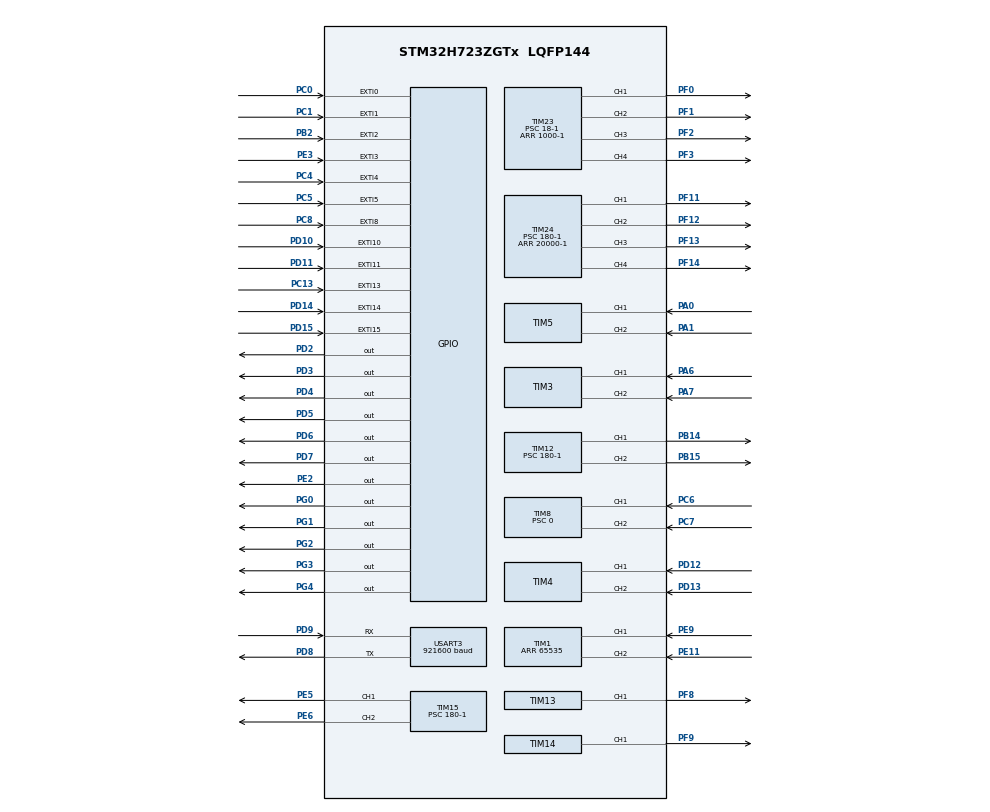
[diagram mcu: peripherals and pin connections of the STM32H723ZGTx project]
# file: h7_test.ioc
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CORTEX_M7.default_mode_Activation=1
Dma.Request0=USART3_RX
Dma.Request1=USART3_TX
Dma.USART3_RX.0.Direction=DMA_PERIPH_TO_MEMORY
Dma.USART3_RX.0.EventEnable=DISABLE
Dma.USART3_RX.0.FIFOMode=DMA_FIFOMODE_DISABLE
Dma.USART3_RX.0.Instance=DMA1_Stream0
Dma.USART3_RX.0.MemDataAlignment=DMA_MDATAALIGN_BYTE
Dma.USART3_RX.0.MemInc=DMA_MINC_ENABLE
Dma.USART3_RX.0.Mode=DMA_CIRCULAR
Dma.USART3_RX.0.PeriphDataAlignment=DMA_PDATAALIGN_BYTE
Dma.USART3_RX.0.PeriphInc=DMA_PINC_DISABLE
Dma.USART3_RX.0.Polarity=HAL_DMAMUX_REQ_GEN_RISING
Dma.USART3_RX.0.Priority=DMA_PRIORITY_VERY_HIGH
Dma.USART3_RX.0.RequestNumber=1
Dma.USART3_RX.0.SignalID=NONE
Dma.USART3_RX.0.SyncEnable=DISABLE
Dma.USART3_RX.0.SyncPolarity=HAL_DMAMUX_SYNC_NO_EVENT
Dma.USART3_RX.0.SyncRequestNumber=1
Dma.USART3_RX.0.SyncSignalID=NONE
Dma.USART3_TX.1.Direction=DMA_MEMORY_TO_PERIPH
Dma.USART3_TX.1.EventEnable=DISABLE
Dma.USART3_TX.1.FIFOMode=DMA_FIFOMODE_DISABLE
Dma.USART3_TX.1.Instance=DMA1_Stream1
Dma.USART3_TX.1.MemDataAlignment=DMA_MDATAALIGN_BYTE
Dma.USART3_TX.1.MemInc=DMA_MINC_ENABLE
Dma.USART3_TX.1.Mode=DMA_NORMAL
Dma.USART3_TX.1.PeriphDataAlignment=DMA_PDATAALIGN_BYTE
Dma.USART3_TX.1.PeriphInc=DMA_PINC_DISABLE
Dma.USART3_TX.1.Polarity=HAL_DMAMUX_REQ_GEN_RISING
Dma.USART3_TX.1.Priority=DMA_PRIORITY_VERY_HIGH
Dma.USART3_TX.1.RequestNumber=1
Dma.USART3_TX.1.SignalID=NONE
Dma.USART3_TX.1.SyncEnable=DISABLE
Dma.USART3_TX.1.SyncPolarity=HAL_DMAMUX_SYNC_NO_EVENT
Dma.USART3_TX.1.SyncRequestNumber=1
Dma.USART3_TX.1.SyncSignalID=NONE
FREERTOS.Tasks01=defaultTask,24,3000,StartDefaultTask,Default,NULL,Dynamic,NULL,NULL
Mcu.Family=STM32H7
Mcu.Name=STM32H723ZGTx
Mcu.Package=LQFP144
NVIC.DMA1_Stream0_IRQn=true\:5\:0\:false\:false\:true\:true\:false\:true\:true
NVIC.DMA1_Stream1_IRQn=true\:5\:0\:false\:false\:true\:true\:false\:true\:true
NVIC.EXTI0_IRQn=true\:5\:0\:false\:false\:true\:true\:true\:true\:true
NVIC.EXTI15_10_IRQn=true\:5\:0\:false\:false\:true\:true\:true\:true\:true
NVIC.EXTI1_IRQn=true\:5\:0\:false\:false\:true\:true\:true\:true\:true
NVIC.EXTI2_IRQn=true\:5\:0\:false\:false\:true\:true\:true\:true\:true
NVIC.EXTI3_IRQn=true\:5\:0\:false\:false\:true\:true\:true\:true\:true
NVIC.PriorityGroup=NVIC_PRIORITYGROUP_4
NVIC.TIM6_DAC_IRQn=true\:15\:0\:false\:false\:true\:false\:false\:true\:true
NVIC.TIM7_IRQn=true\:5\:0\:false\:false\:true\:true\:true\:true\:true
NVIC.TimeBase=TIM6_DAC_IRQn
NVIC.TimeBaseIP=TIM6
NVIC.USART3_IRQn=true\:5\:0\:false\:false\:true\:true\:true\:true\:true
PA0.Signal=S_TIM5_CH1
PA1.Signal=S_TIM5_CH2
PA13(JTMS/SWDIO).Mode=Serial_Wire
PA13(JTMS/SWDIO).Signal=DEBUG_JTMS-SWDIO
PA14(JTCK/SWCLK).Mode=Serial_Wire
PA14(JTCK/SWCLK).Signal=DEBUG_JTCK-SWCLK
PA6.Signal=S_TIM3_CH1
PA7.Signal=S_TIM3_CH2
PB14.Signal=S_TIM12_CH1
PB15.Signal=S_TIM12_CH2
PB2.GPIO_ModeDefaultEXTI=GPIO_MODE_IT_FALLING
PB2.GPIO_PuPd=GPIO_PULLUP
PB2.Signal=GPXTI2
PC0.GPIO_ModeDefaultEXTI=GPIO_MODE_IT_FALLING
PC0.GPIO_PuPd=GPIO_PULLUP
PC0.Signal=GPXTI0
PC1.GPIO_ModeDefaultEXTI=GPIO_MODE_IT_FALLING
PC1.GPIO_PuPd=GPIO_PULLUP
PC1.Signal=GPXTI1
PC13.GPIO_ModeDefaultEXTI=GPIO_MODE_IT_FALLING
PC13.GPIO_PuPd=GPIO_PULLUP
PC13.Signal=GPXTI13
PC14-OSC32_IN.Mode=LSE-External-Oscillator
PC14-OSC32_IN.Signal=RCC_OSC32_IN
PC15-OSC32_OUT.Mode=LSE-External-Oscillator
PC15-OSC32_OUT.Signal=RCC_OSC32_OUT
PC4.GPIO_ModeDefaultEXTI=GPIO_MODE_IT_FALLING
PC4.GPIO_PuPd=GPIO_PULLUP
PC4.Signal=GPXTI4
PC5.GPIO_ModeDefaultEXTI=GPIO_MODE_IT_FALLING
PC5.GPIO_PuPd=GPIO_PULLUP
PC5.Signal=GPXTI5
PC6.Signal=S_TIM8_CH1
PC7.Signal=S_TIM8_CH2
PC8.GPIO_ModeDefaultEXTI=GPIO_MODE_IT_FALLING
PC8.GPIO_PuPd=GPIO_PULLUP
PC8.Signal=GPXTI8
PD10.GPIO_ModeDefaultEXTI=GPIO_MODE_IT_FALLING
PD10.GPIO_PuPd=GPIO_PULLUP
PD10.Signal=GPXTI10
PD11.GPIO_ModeDefaultEXTI=GPIO_MODE_IT_FALLING
PD11.GPIO_PuPd=GPIO_PULLUP
PD11.Signal=GPXTI11
PD12.Signal=S_TIM4_CH1
PD13.Signal=S_TIM4_CH2
PD14.GPIO_ModeDefaultEXTI=GPIO_MODE_IT_FALLING
PD14.GPIO_PuPd=GPIO_PULLUP
PD14.Signal=GPXTI14
PD15.GPIO_ModeDefaultEXTI=GPIO_MODE_IT_FALLING
PD15.GPIO_PuPd=GPIO_PULLUP
PD15.Signal=GPXTI15
PD2.Signal=GPIO_Output
PD3.Signal=GPIO_Output
PD4.Signal=GPIO_Output
PD5.Signal=GPIO_Output
PD6.Signal=GPIO_Output
PD7.Signal=GPIO_Output
PD8.Mode=Asynchronous
PD8.Signal=USART3_TX
PD9.Mode=Asynchronous
PD9.Signal=USART3_RX
PE11.Signal=S_TIM1_CH2
PE2.Signal=GPIO_Output
PE3.GPIO_ModeDefaultEXTI=GPIO_MODE_IT_FALLING
PE3.GPIO_PuPd=GPIO_PULLUP
PE3.Signal=GPXTI3
PE5.Signal=S_TIM15_CH1
PE6.Signal=S_TIM15_CH2
PE9.Signal=S_TIM1_CH1
PF0.Mode=PWM Generation1 CH1
PF0.Signal=TIM23_CH1
PF1.Signal=S_TIM23_CH2
PF11.Mode=PWM Generation1 CH1
PF11.Signal=TIM24_CH1
PF12.Signal=S_TIM24_CH2
PF13.Signal=S_TIM24_CH3
PF14.Signal=S_TIM24_CH4
PF2.Signal=S_TIM23_CH3
PF3.Signal=S_TIM23_CH4
PF8.Signal=S_TIM13_CH1
PF9.Signal=S_TIM14_CH1
PG0.Signal=GPIO_Output
PG1.Signal=GPIO_Output
PG2.Signal=GPIO_Output
PG3.Signal=GPIO_Output
PG4.Signal=GPIO_Output
ProjectManager.HeapSize=0x200
ProjectManager.StackSize=0x400
ProjectManager.TargetToolchain=STM32CubeIDE
RCC.ADCFreq_Value=129000000
RCC.APB1Freq_Value=90000000
RCC.APB2Freq_Value=90000000
RCC.APB3Freq_Value=90000000
RCC.APB4Freq_Value=90000000
RCC.CortexFreq_Value=180000000
RCC.D1CPRE=RCC_SYSCLK_DIV2
RCC.D1PPRE=RCC_APB3_DIV2
RCC.D2PPRE1=RCC_APB1_DIV2
RCC.D2PPRE2=RCC_APB2_DIV2
RCC.D3PPRE=RCC_APB4_DIV2
RCC.DIVM1=4
RCC.DIVN1=22
RCC.DIVP1=1
RCC.HCLKFreq_Value=180000000
RCC.PLL2FRACN=0
RCC.PLL3FRACN=0
RCC.PLLFRACN=4096
RCC.SYSCLKFreq_VALUE=360000000
RCC.SYSCLKSource=RCC_SYSCLKSOURCE_PLLCLK
RCC.USBFreq_Value=180000000
SH.S_TIM12_CH1.0=TIM12_CH1,PWM Generation1 CH1
SH.S_TIM12_CH2.0=TIM12_CH2,PWM Generation2 CH2
SH.S_TIM13_CH1.0=TIM13_CH1,PWM Generation1 CH1
SH.S_TIM14_CH1.0=TIM14_CH1,PWM Generation1 CH1
SH.S_TIM15_CH1.0=TIM15_CH1,PWM Generation1 CH1
SH.S_TIM15_CH2.0=TIM15_CH2,PWM Generation2 CH2
SH.S_TIM1_CH1.0=TIM1_CH1,Encoder_Interface
SH.S_TIM1_CH2.0=TIM1_CH2,Encoder_Interface
SH.S_TIM23_CH2.0=TIM23_CH2,PWM Generation2 CH2
SH.S_TIM23_CH3.0=TIM23_CH3,PWM Generation3 CH3
SH.S_TIM23_CH4.0=TIM23_CH4,PWM Generation4 CH4
SH.S_TIM24_CH2.0=TIM24_CH2,PWM Generation2 CH2
SH.S_TIM24_CH3.0=TIM24_CH3,PWM Generation3 CH3
SH.S_TIM24_CH4.0=TIM24_CH4,PWM Generation4 CH4
SH.S_TIM3_CH1.0=TIM3_CH1,Encoder_Interface
SH.S_TIM3_CH2.0=TIM3_CH2,Encoder_Interface
SH.S_TIM4_CH1.0=TIM4_CH1,Encoder_Interface
SH.S_TIM4_CH2.0=TIM4_CH2,Encoder_Interface
SH.S_TIM5_CH1.0=TIM5_CH1,Encoder_Interface
SH.S_TIM5_CH2.0=TIM5_CH2,Encoder_Interface
SH.S_TIM8_CH1.0=TIM8_CH1,Encoder_Interface
SH.S_TIM8_CH2.0=TIM8_CH2,Encoder_Interface
TIM1.IC1Filter=8
TIM1.IC2Filter=8
TIM1.Period=65535
TIM12.Channel-PWM\ Generation1\ CH1=TIM_CHANNEL_1
TIM12.Channel-PWM\ Generation2\ CH2=TIM_CHANNEL_2
TIM12.Period=20000-1
TIM12.Prescaler=180-1
TIM13.Channel=TIM_CHANNEL_1
TIM13.Period=1000-1
TIM13.Prescaler=18-1
TIM14.Channel=TIM_CHANNEL_1
TIM15.Channel-PWM\ Generation1\ CH1=TIM_CHANNEL_1
TIM15.Channel-PWM\ Generation2\ CH2=TIM_CHANNEL_2
TIM15.Period=20000-1
TIM15.Prescaler=180-1
TIM23.Channel-PWM\ Generation1\ CH1=TIM_CHANNEL_1
TIM23.Channel-PWM\ Generation2\ CH2=TIM_CHANNEL_2
TIM23.Channel-PWM\ Generation3\ CH3=TIM_CHANNEL_3
TIM23.Channel-PWM\ Generation4\ CH4=TIM_CHANNEL_4
TIM23.Period=1000-1
TIM23.Prescaler=18-1
TIM24.Channel-PWM\ Generation1\ CH1=TIM_CHANNEL_1
TIM24.Channel-PWM\ Generation2\ CH2=TIM_CHANNEL_2
TIM24.Channel-PWM\ Generation3\ CH3=TIM_CHANNEL_3
TIM24.Channel-PWM\ Generation4\ CH4=TIM_CHANNEL_4
TIM24.Period=20000-1
TIM24.Prescaler=180-1
TIM3.IC1Filter=8
TIM3.IC2Filter=8
TIM4.IC1Filter=8
TIM4.IC2Filter=8
TIM5.EncoderMode=TIM_ENCODERMODE_TI1
TIM5.IC1Filter=8
TIM5.IC2Filter=8
TIM7.Period=1000-1
TIM7.Prescaler=180-1
TIM8.EncoderMode=TIM_ENCODERMODE_TI1
TIM8.IC1Filter=8
TIM8.IC2Filter=8
TIM8.Period=65535
TIM8.Prescaler=0
USART3.BaudRate=921600
USART3.VirtualMode-Asynchronous=VM_ASYNC
VP_FREERTOS_VS_CMSIS_V2.Mode=CMSIS_V2
VP_MEMORYMAP_VS_MEMORYMAP.Mode=CurAppReg
VP_SYS_VS_tim6.Mode=TIM6
VP_TIM13_VS_ClockSourceINT.Mode=Enable_Timer
VP_TIM14_VS_ClockSourceINT.Mode=Enable_Timer
VP_TIM7_VS_ClockSourceINT.Mode=Enable_Timer
board=custom

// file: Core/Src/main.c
/* USER CODE BEGIN Header */
/**
  ******************************************************************************
  * @file           : main.c
  * @brief          : Main program body
  ******************************************************************************
  * @attention
  *
  * Copyright (c) 2026 STMicroelectronics.
  * All rights reserved.
  *
  * This software is licensed under terms that can be found in the LICENSE file
  * in the root directory of this software component.
  * If no LICENSE file comes with this software, it is provided AS-IS.
  *
  ******************************************************************************
  */
/* USER CODE END Header */
#include "main.h"
#include "cmsis_os.h"

TIM_HandleTypeDef htim1;
TIM_HandleTypeDef htim3;
TIM_HandleTypeDef htim4;
TIM_HandleTypeDef htim5;
TIM_HandleTypeDef htim7;
TIM_HandleTypeDef htim8;
TIM_HandleTypeDef htim12;
TIM_HandleTypeDef htim13;
TIM_HandleTypeDef htim14;
TIM_HandleTypeDef htim15;
TIM_HandleTypeDef htim23;
TIM_HandleTypeDef htim24;

UART_HandleTypeDef huart3;
DMA_HandleTypeDef hdma_usart3_rx;
DMA_HandleTypeDef hdma_usart3_tx;

/* Definitions for defaultTask */
osThreadId_t defaultTaskHandle;
const osThreadAttr_t defaultTask_attributes = {
  .name = "defaultTask",
  .stack_size = 3000 * 4,
  .priority = (osPriority_t) osPriorityNormal,
};

void SystemClock_Config(void);
static void MPU_Config(void);
static void MX_GPIO_Init(void);
static void MX_DMA_Init(void);
static void MX_TIM5_Init(void);
static void MX_USART3_UART_Init(void);
static void MX_TIM1_Init(void);
static void MX_TIM3_Init(void);
static void MX_TIM4_Init(void);
static void MX_TIM8_Init(void);
static void MX_TIM7_Init(void);
static void MX_TIM12_Init(void);
static void MX_TIM13_Init(void);
static void MX_TIM14_Init(void);
static void MX_TIM15_Init(void);
static void MX_TIM23_Init(void);
static void MX_TIM24_Init(void);
void StartDefaultTask(void *argument);

int main(void)
{

  /* MPU Configuration--------------------------------------------------------*/
  MPU_Config();

  /* MCU Configuration--------------------------------------------------------*/

  /* Reset of all peripherals, Initializes the Flash interface and the Systick. */
  HAL_Init();

  /* Configure the system clock */
  SystemClock_Config();

  /* Initialize all configured peripherals */
  MX_GPIO_Init();
  MX_DMA_Init();
  MX_TIM5_Init();
  MX_USART3_UART_Init();
  MX_TIM1_Init();
  MX_TIM3_Init();
  MX_TIM4_Init();
  MX_TIM8_Init();
  MX_TIM7_Init();
  MX_TIM12_Init();
  MX_TIM13_Init();
  MX_TIM14_Init();
  MX_TIM15_Init();
  MX_TIM23_Init();
  MX_TIM24_Init();

  /* Init scheduler */
  osKernelInitialize();

  /* Create the thread(s) */
  /* creation of defaultTask */
  defaultTaskHandle = osThreadNew(StartDefaultTask, NULL, &defaultTask_attributes);

  /* Start scheduler */
  osKernelStart();

  /* We should never get here as control is now taken by the scheduler */

  /* Infinite loop */
  while (1)
  {

  }
}

void SystemClock_Config(void)
{
  RCC_OscInitTypeDef RCC_OscInitStruct = {0};
  RCC_ClkInitTypeDef RCC_ClkInitStruct = {0};

  /** Supply configuration update enable
  */
  HAL_PWREx_ConfigSupply(PWR_LDO_SUPPLY);

  /** Configure the main internal regulator output voltage
  */
  __HAL_PWR_VOLTAGESCALING_CONFIG(PWR_REGULATOR_VOLTAGE_SCALE1);

  while(!__HAL_PWR_GET_FLAG(PWR_FLAG_VOSRDY)) {}

  /** Initializes the RCC Oscillators according to the specified parameters
  * in the RCC_OscInitTypeDef structure.
  */
  RCC_OscInitStruct.OscillatorType = RCC_OSCILLATORTYPE_HSI;
  RCC_OscInitStruct.HSIState = RCC_HSI_DIV1;
  RCC_OscInitStruct.HSICalibrationValue = 64;
  RCC_OscInitStruct.PLL.PLLState = RCC_PLL_ON;
  RCC_OscInitStruct.PLL.PLLSource = RCC_PLLSOURCE_HSI;
  RCC_OscInitStruct.PLL.PLLM = 4;
  RCC_OscInitStruct.PLL.PLLN = 22;
  RCC_OscInitStruct.PLL.PLLP = 1;
  RCC_OscInitStruct.PLL.PLLQ = 2;
  RCC_OscInitStruct.PLL.PLLR = 2;
  RCC_OscInitStruct.PLL.PLLRGE = RCC_PLL1VCIRANGE_3;
  RCC_OscInitStruct.PLL.PLLVCOSEL = RCC_PLL1VCOWIDE;
  RCC_OscInitStruct.PLL.PLLFRACN = 4096;
  if (HAL_RCC_OscConfig(&RCC_OscInitStruct) != HAL_OK)
  {
    Error_Handler();
  }

  /** Initializes the CPU, AHB and APB buses clocks
  */
  RCC_ClkInitStruct.ClockType = RCC_CLOCKTYPE_HCLK|RCC_CLOCKTYPE_SYSCLK
                              |RCC_CLOCKTYPE_PCLK1|RCC_CLOCKTYPE_PCLK2
                              |RCC_CLOCKTYPE_D3PCLK1|RCC_CLOCKTYPE_D1PCLK1;
  RCC_ClkInitStruct.SYSCLKSource = RCC_SYSCLKSOURCE_PLLCLK;
  RCC_ClkInitStruct.SYSCLKDivider = RCC_SYSCLK_DIV2;
  RCC_ClkInitStruct.AHBCLKDivider = RCC_HCLK_DIV1;
  RCC_ClkInitStruct.APB3CLKDivider = RCC_APB3_DIV2;
  RCC_ClkInitStruct.APB1CLKDivider = RCC_APB1_DIV2;
  RCC_ClkInitStruct.APB2CLKDivider = RCC_APB2_DIV2;
  RCC_ClkInitStruct.APB4CLKDivider = RCC_APB4_DIV2;

  if (HAL_RCC_ClockConfig(&RCC_ClkInitStruct, FLASH_LATENCY_2) != HAL_OK)
  {
    Error_Handler();
  }
}

static void MX_TIM1_Init(void)
{

  TIM_Encoder_InitTypeDef sConfig = {0};
  TIM_MasterConfigTypeDef sMasterConfig = {0};

  htim1.Instance = TIM1;
  htim1.Init.Prescaler = 0;
  htim1.Init.CounterMode = TIM_COUNTERMODE_UP;
  htim1.Init.Period = 65535;
  htim1.Init.ClockDivision = TIM_CLOCKDIVISION_DIV1;
  htim1.Init.RepetitionCounter = 0;
  htim1.Init.AutoReloadPreload = TIM_AUTORELOAD_PRELOAD_DISABLE;
  sConfig.EncoderMode = TIM_ENCODERMODE_TI1;
  sConfig.IC1Polarity = TIM_ICPOLARITY_RISING;
  sConfig.IC1Selection = TIM_ICSELECTION_DIRECTTI;
  sConfig.IC1Prescaler = TIM_ICPSC_DIV1;
  sConfig.IC1Filter = 8;
  sConfig.IC2Polarity = TIM_ICPOLARITY_RISING;
  sConfig.IC2Selection = TIM_ICSELECTION_DIRECTTI;
  sConfig.IC2Prescaler = TIM_ICPSC_DIV1;
  sConfig.IC2Filter = 8;
  if (HAL_TIM_Encoder_Init(&htim1, &sConfig) != HAL_OK)
  {
    Error_Handler();
  }
  sMasterConfig.MasterOutputTrigger = TIM_TRGO_RESET;
  sMasterConfig.MasterOutputTrigger2 = TIM_TRGO2_RESET;
  sMasterConfig.MasterSlaveMode = TIM_MASTERSLAVEMODE_DISABLE;
  if (HAL_TIMEx_MasterConfigSynchronization(&htim1, &sMasterConfig) != HAL_OK)
  {
    Error_Handler();
  }

}

static void MX_TIM3_Init(void)
{

  TIM_Encoder_InitTypeDef sConfig = {0};
  TIM_MasterConfigTypeDef sMasterConfig = {0};

  htim3.Instance = TIM3;
  htim3.Init.Prescaler = 0;
  htim3.Init.CounterMode = TIM_COUNTERMODE_UP;
  htim3.Init.Period = 65535;
  htim3.Init.ClockDivision = TIM_CLOCKDIVISION_DIV1;
  htim3.Init.AutoReloadPreload = TIM_AUTORELOAD_PRELOAD_DISABLE;
  sConfig.EncoderMode = TIM_ENCODERMODE_TI1;
  sConfig.IC1Polarity = TIM_ICPOLARITY_RISING;
  sConfig.IC1Selection = TIM_ICSELECTION_DIRECTTI;
  sConfig.IC1Prescaler = TIM_ICPSC_DIV1;
  sConfig.IC1Filter = 8;
  sConfig.IC2Polarity = TIM_ICPOLARITY_RISING;
  sConfig.IC2Selection = TIM_ICSELECTION_DIRECTTI;
  sConfig.IC2Prescaler = TIM_ICPSC_DIV1;
  sConfig.IC2Filter = 8;
  if (HAL_TIM_Encoder_Init(&htim3, &sConfig) != HAL_OK)
  {
    Error_Handler();
  }
  sMasterConfig.MasterOutputTrigger = TIM_TRGO_RESET;
  sMasterConfig.MasterSlaveMode = TIM_MASTERSLAVEMODE_DISABLE;
  if (HAL_TIMEx_MasterConfigSynchronization(&htim3, &sMasterConfig) != HAL_OK)
  {
    Error_Handler();
  }

}

static void MX_TIM4_Init(void)
{

  TIM_Encoder_InitTypeDef sConfig = {0};
  TIM_MasterConfigTypeDef sMasterConfig = {0};

  htim4.Instance = TIM4;
  htim4.Init.Prescaler = 0;
  htim4.Init.CounterMode = TIM_COUNTERMODE_UP;
  htim4.Init.Period = 65535;
  htim4.Init.ClockDivision = TIM_CLOCKDIVISION_DIV1;
  htim4.Init.AutoReloadPreload = TIM_AUTORELOAD_PRELOAD_DISABLE;
  sConfig.EncoderMode = TIM_ENCODERMODE_TI1;
  sConfig.IC1Polarity = TIM_ICPOLARITY_RISING;
  sConfig.IC1Selection = TIM_ICSELECTION_DIRECTTI;
  sConfig.IC1Prescaler = TIM_ICPSC_DIV1;
  sConfig.IC1Filter = 8;
  sConfig.IC2Polarity = TIM_ICPOLARITY_RISING;
  sConfig.IC2Selection = TIM_ICSELECTION_DIRECTTI;
  sConfig.IC2Prescaler = TIM_ICPSC_DIV1;
  sConfig.IC2Filter = 8;
  if (HAL_TIM_Encoder_Init(&htim4, &sConfig) != HAL_OK)
  {
    Error_Handler();
  }
  sMasterConfig.MasterOutputTrigger = TIM_TRGO_RESET;
  sMasterConfig.MasterSlaveMode = TIM_MASTERSLAVEMODE_DISABLE;
  if (HAL_TIMEx_MasterConfigSynchronization(&htim4, &sMasterConfig) != HAL_OK)
  {
    Error_Handler();
  }

}

static void MX_TIM5_Init(void)
{

  TIM_Encoder_InitTypeDef sConfig = {0};
  TIM_MasterConfigTypeDef sMasterConfig = {0};

  htim5.Instance = TIM5;
  htim5.Init.Prescaler = 0;
  htim5.Init.CounterMode = TIM_COUNTERMODE_UP;
  htim5.Init.Period = 4294967295;
  htim5.Init.ClockDivision = TIM_CLOCKDIVISION_DIV1;
  htim5.Init.AutoReloadPreload = TIM_AUTORELOAD_PRELOAD_DISABLE;
  sConfig.EncoderMode = TIM_ENCODERMODE_TI1;
  sConfig.IC1Polarity = TIM_ICPOLARITY_RISING;
  sConfig.IC1Selection = TIM_ICSELECTION_DIRECTTI;
  sConfig.IC1Prescaler = TIM_ICPSC_DIV1;
  sConfig.IC1Filter = 8;
  sConfig.IC2Polarity = TIM_ICPOLARITY_RISING;
  sConfig.IC2Selection = TIM_ICSELECTION_DIRECTTI;
  sConfig.IC2Prescaler = TIM_ICPSC_DIV1;
  sConfig.IC2Filter = 8;
  if (HAL_TIM_Encoder_Init(&htim5, &sConfig) != HAL_OK)
  {
    Error_Handler();
  }
  sMasterConfig.MasterOutputTrigger = TIM_TRGO_RESET;
  sMasterConfig.MasterSlaveMode = TIM_MASTERSLAVEMODE_DISABLE;
  if (HAL_TIMEx_MasterConfigSynchronization(&htim5, &sMasterConfig) != HAL_OK)
  {
    Error_Handler();
  }

}

static void MX_TIM7_Init(void)
{

  TIM_MasterConfigTypeDef sMasterConfig = {0};

  htim7.Instance = TIM7;
  htim7.Init.Prescaler = 180-1;
  htim7.Init.CounterMode = TIM_COUNTERMODE_UP;
  htim7.Init.Period = 1000-1;
  htim7.Init.AutoReloadPreload = TIM_AUTORELOAD_PRELOAD_DISABLE;
  if (HAL_TIM_Base_Init(&htim7) != HAL_OK)
  {
    Error_Handler();
  }
  sMasterConfig.MasterOutputTrigger = TIM_TRGO_RESET;
  sMasterConfig.MasterSlaveMode = TIM_MASTERSLAVEMODE_DISABLE;
  if (HAL_TIMEx_MasterConfigSynchronization(&htim7, &sMasterConfig) != HAL_OK)
  {
    Error_Handler();
  }

}

static void MX_TIM8_Init(void)
{

  TIM_Encoder_InitTypeDef sConfig = {0};
  TIM_MasterConfigTypeDef sMasterConfig = {0};

  htim8.Instance = TIM8;
  htim8.Init.Prescaler = 0;
  htim8.Init.CounterMode = TIM_COUNTERMODE_UP;
  htim8.Init.Period = 65535;
  htim8.Init.ClockDivision = TIM_CLOCKDIVISION_DIV1;
  htim8.Init.RepetitionCounter = 0;
  htim8.Init.AutoReloadPreload = TIM_AUTORELOAD_PRELOAD_DISABLE;
  sConfig.EncoderMode = TIM_ENCODERMODE_TI1;
  sConfig.IC1Polarity = TIM_ICPOLARITY_RISING;
  sConfig.IC1Selection = TIM_ICSELECTION_DIRECTTI;
  sConfig.IC1Prescaler = TIM_ICPSC_DIV1;
  sConfig.IC1Filter = 8;
  sConfig.IC2Polarity = TIM_ICPOLARITY_RISING;
  sConfig.IC2Selection = TIM_ICSELECTION_DIRECTTI;
  sConfig.IC2Prescaler = TIM_ICPSC_DIV1;
  sConfig.IC2Filter = 8;
  if (HAL_TIM_Encoder_Init(&htim8, &sConfig) != HAL_OK)
  {
    Error_Handler();
  }
  sMasterConfig.MasterOutputTrigger = TIM_TRGO_RESET;
  sMasterConfig.MasterOutputTrigger2 = TIM_TRGO2_RESET;
  sMasterConfig.MasterSlaveMode = TIM_MASTERSLAVEMODE_DISABLE;
  if (HAL_TIMEx_MasterConfigSynchronization(&htim8, &sMasterConfig) != HAL_OK)
  {
    Error_Handler();
  }

}

static void MX_TIM12_Init(void)
{

  TIM_MasterConfigTypeDef sMasterConfig = {0};
  TIM_OC_InitTypeDef sConfigOC = {0};

  htim12.Instance = TIM12;
  htim12.Init.Prescaler = 180-1;
  htim12.Init.CounterMode = TIM_COUNTERMODE_UP;
  htim12.Init.Period = 20000-1;
  htim12.Init.ClockDivision = TIM_CLOCKDIVISION_DIV1;
  htim12.Init.AutoReloadPreload = TIM_AUTORELOAD_PRELOAD_DISABLE;
  if (HAL_TIM_PWM_Init(&htim12) != HAL_OK)
  {
    Error_Handler();
  }
  sMasterConfig.MasterOutputTrigger = TIM_TRGO_RESET;
  sMasterConfig.MasterSlaveMode = TIM_MASTERSLAVEMODE_DISABLE;
  if (HAL_TIMEx_MasterConfigSynchronization(&htim12, &sMasterConfig) != HAL_OK)
  {
    Error_Handler();
  }
  sConfigOC.OCMode = TIM_OCMODE_PWM1;
  sConfigOC.Pulse = 0;
  sConfigOC.OCPolarity = TIM_OCPOLARITY_HIGH;
  sConfigOC.OCFastMode = TIM_OCFAST_DISABLE;
  if (HAL_TIM_PWM_ConfigChannel(&htim12, &sConfigOC, TIM_CHANNEL_1) != HAL_OK)
  {
    Error_Handler();
  }
  if (HAL_TIM_PWM_ConfigChannel(&htim12, &sConfigOC, TIM_CHANNEL_2) != HAL_OK)
  {
    Error_Handler();
  }
  HAL_TIM_MspPostInit(&htim12);

}

static void MX_TIM13_Init(void)
{

  TIM_OC_InitTypeDef sConfigOC = {0};

  htim13.Instance = TIM13;
  htim13.Init.Prescaler = 18-1;
  htim13.Init.CounterMode = TIM_COUNTERMODE_UP;
  htim13.Init.Period = 1000-1;
  htim13.Init.ClockDivision = TIM_CLOCKDIVISION_DIV1;
  htim13.Init.AutoReloadPreload = TIM_AUTORELOAD_PRELOAD_DISABLE;
  if (HAL_TIM_Base_Init(&htim13) != HAL_OK)
  {
    Error_Handler();
  }
  if (HAL_TIM_PWM_Init(&htim13) != HAL_OK)
  {
    Error_Handler();
  }
  sConfigOC.OCMode = TIM_OCMODE_PWM1;
  sConfigOC.Pulse = 0;
  sConfigOC.OCPolarity = TIM_OCPOLARITY_HIGH;
  sConfigOC.OCFastMode = TIM_OCFAST_DISABLE;
  if (HAL_TIM_PWM_ConfigChannel(&htim13, &sConfigOC, TIM_CHANNEL_1) != HAL_OK)
  {
    Error_Handler();
  }
  HAL_TIM_MspPostInit(&htim13);

}

static void MX_TIM14_Init(void)
{

  TIM_OC_InitTypeDef sConfigOC = {0};

  htim14.Instance = TIM14;
  htim14.Init.Prescaler = 0;
  htim14.Init.CounterMode = TIM_COUNTERMODE_UP;
  htim14.Init.Period = 65535;
  htim14.Init.ClockDivision = TIM_CLOCKDIVISION_DIV1;
  htim14.Init.AutoReloadPreload = TIM_AUTORELOAD_PRELOAD_DISABLE;
  if (HAL_TIM_Base_Init(&htim14) != HAL_OK)
  {
    Error_Handler();
  }
  if (HAL_TIM_PWM_Init(&htim14) != HAL_OK)
  {
    Error_Handler();
  }
  sConfigOC.OCMode = TIM_OCMODE_PWM1;
  sConfigOC.Pulse = 0;
  sConfigOC.OCPolarity = TIM_OCPOLARITY_HIGH;
  sConfigOC.OCFastMode = TIM_OCFAST_DISABLE;
  if (HAL_TIM_PWM_ConfigChannel(&htim14, &sConfigOC, TIM_CHANNEL_1) != HAL_OK)
  {
    Error_Handler();
  }
  HAL_TIM_MspPostInit(&htim14);

}

static void MX_TIM15_Init(void)
{

  TIM_MasterConfigTypeDef sMasterConfig = {0};
  TIM_OC_InitTypeDef sConfigOC = {0};
  TIM_BreakDeadTimeConfigTypeDef sBreakDeadTimeConfig = {0};

  htim15.Instance = TIM15;
  htim15.Init.Prescaler = 180-1;
  htim15.Init.CounterMode = TIM_COUNTERMODE_UP;
  htim15.Init.Period = 20000-1;
  htim15.Init.ClockDivision = TIM_CLOCKDIVISION_DIV1;
  htim15.Init.RepetitionCounter = 0;
  htim15.Init.AutoReloadPreload = TIM_AUTORELOAD_PRELOAD_DISABLE;
  if (HAL_TIM_PWM_Init(&htim15) != HAL_OK)
  {
    Error_Handler();
  }
  sMasterConfig.MasterOutputTrigger = TIM_TRGO_RESET;
  sMasterConfig.MasterSlaveMode = TIM_MASTERSLAVEMODE_DISABLE;
  if (HAL_TIMEx_MasterConfigSynchronization(&htim15, &sMasterConfig) != HAL_OK)
  {
    Error_Handler();
  }
  sConfigOC.OCMode = TIM_OCMODE_PWM1;
  sConfigOC.Pulse = 0;
  sConfigOC.OCPolarity = TIM_OCPOLARITY_HIGH;
  sConfigOC.OCNPolarity = TIM_OCNPOLARITY_HIGH;
  sConfigOC.OCFastMode = TIM_OCFAST_DISABLE;
  sConfigOC.OCIdleState = TIM_OCIDLESTATE_RESET;
  sConfigOC.OCNIdleState = TIM_OCNIDLESTATE_RESET;
  if (HAL_TIM_PWM_ConfigChannel(&htim15, &sConfigOC, TIM_CHANNEL_1) != HAL_OK)
  {
    Error_Handler();
  }
  if (HAL_TIM_PWM_ConfigChannel(&htim15, &sConfigOC, TIM_CHANNEL_2) != HAL_OK)
  {
    Error_Handler();
  }
  sBreakDeadTimeConfig.OffStateRunMode = TIM_OSSR_DISABLE;
  sBreakDeadTimeConfig.OffStateIDLEMode = TIM_OSSI_DISABLE;
  sBreakDeadTimeConfig.LockLevel = TIM_LOCKLEVEL_OFF;
  sBreakDeadTimeConfig.DeadTime = 0;
  sBreakDeadTimeConfig.BreakState = TIM_BREAK_DISABLE;
  sBreakDeadTimeConfig.BreakPolarity = TIM_BREAKPOLARITY_HIGH;
  sBreakDeadTimeConfig.BreakFilter = 0;
  sBreakDeadTimeConfig.AutomaticOutput = TIM_AUTOMATICOUTPUT_DISABLE;
  if (HAL_TIMEx_ConfigBreakDeadTime(&htim15, &sBreakDeadTimeConfig) != HAL_OK)
  {
    Error_Handler();
  }
  HAL_TIM_MspPostInit(&htim15);

}

static void MX_TIM23_Init(void)
{

  TIM_MasterConfigTypeDef sMasterConfig = {0};
  TIM_OC_InitTypeDef sConfigOC = {0};

  htim23.Instance = TIM23;
  htim23.Init.Prescaler = 18-1;
  htim23.Init.CounterMode = TIM_COUNTERMODE_UP;
  htim23.Init.Period = 1000-1;
  htim23.Init.ClockDivision = TIM_CLOCKDIVISION_DIV1;
  htim23.Init.AutoReloadPreload = TIM_AUTORELOAD_PRELOAD_DISABLE;
  if (HAL_TIM_PWM_Init(&htim23) != HAL_OK)
  {
    Error_Handler();
  }
  sMasterConfig.MasterOutputTrigger = TIM_TRGO_RESET;
  sMasterConfig.MasterSlaveMode = TIM_MASTERSLAVEMODE_DISABLE;
  if (HAL_TIMEx_MasterConfigSynchronization(&htim23, &sMasterConfig) != HAL_OK)
  {
    Error_Handler();
  }
  sConfigOC.OCMode = TIM_OCMODE_PWM1;
  sConfigOC.Pulse = 0;
  sConfigOC.OCPolarity = TIM_OCPOLARITY_HIGH;
  sConfigOC.OCFastMode = TIM_OCFAST_DISABLE;
  if (HAL_TIM_PWM_ConfigChannel(&htim23, &sConfigOC, TIM_CHANNEL_1) != HAL_OK)
  {
    Error_Handler();
  }
  if (HAL_TIM_PWM_ConfigChannel(&htim23, &sConfigOC, TIM_CHANNEL_2) != HAL_OK)
  {
    Error_Handler();
  }
  if (HAL_TIM_PWM_ConfigChannel(&htim23, &sConfigOC, TIM_CHANNEL_3) != HAL_OK)
  {
    Error_Handler();
  }
  if (HAL_TIM_PWM_ConfigChannel(&htim23, &sConfigOC, TIM_CHANNEL_4) != HAL_OK)
  {
    Error_Handler();
  }
  HAL_TIM_MspPostInit(&htim23);

}

static void MX_TIM24_Init(void)
{

  TIM_MasterConfigTypeDef sMasterConfig = {0};
  TIM_OC_InitTypeDef sConfigOC = {0};

  htim24.Instance = TIM24;
  htim24.Init.Prescaler = 180-1;
  htim24.Init.CounterMode = TIM_COUNTERMODE_UP;
  htim24.Init.Period = 20000-1;
  htim24.Init.ClockDivision = TIM_CLOCKDIVISION_DIV1;
  htim24.Init.AutoReloadPreload = TIM_AUTORELOAD_PRELOAD_DISABLE;
  if (HAL_TIM_PWM_Init(&htim24) != HAL_OK)
  {
    Error_Handler();
  }
  sMasterConfig.MasterOutputTrigger = TIM_TRGO_RESET;
  sMasterConfig.MasterSlaveMode = TIM_MASTERSLAVEMODE_DISABLE;
  if (HAL_TIMEx_MasterConfigSynchronization(&htim24, &sMasterConfig) != HAL_OK)
  {
    Error_Handler();
  }
  sConfigOC.OCMode = TIM_OCMODE_PWM1;
  sConfigOC.Pulse = 0;
  sConfigOC.OCPolarity = TIM_OCPOLARITY_HIGH;
  sConfigOC.OCFastMode = TIM_OCFAST_DISABLE;
  if (HAL_TIM_PWM_ConfigChannel(&htim24, &sConfigOC, TIM_CHANNEL_1) != HAL_OK)
  {
    Error_Handler();
  }
  if (HAL_TIM_PWM_ConfigChannel(&htim24, &sConfigOC, TIM_CHANNEL_2) != HAL_OK)
  {
    Error_Handler();
  }
  if (HAL_TIM_PWM_ConfigChannel(&htim24, &sConfigOC, TIM_CHANNEL_3) != HAL_OK)
  {
    Error_Handler();
  }
  if (HAL_TIM_PWM_ConfigChannel(&htim24, &sConfigOC, TIM_CHANNEL_4) != HAL_OK)
  {
    Error_Handler();
  }
  HAL_TIM_MspPostInit(&htim24);

}

static void MX_USART3_UART_Init(void)
{

  huart3.Instance = USART3;
  huart3.Init.BaudRate = 921600;
  huart3.Init.WordLength = UART_WORDLENGTH_8B;
  huart3.Init.StopBits = UART_STOPBITS_1;
  huart3.Init.Parity = UART_PARITY_NONE;
  huart3.Init.Mode = UART_MODE_TX_RX;
  huart3.Init.HwFlowCtl = UART_HWCONTROL_NONE;
  huart3.Init.OverSampling = UART_OVERSAMPLING_16;
  huart3.Init.OneBitSampling = UART_ONE_BIT_SAMPLE_DISABLE;
  huart3.Init.ClockPrescaler = UART_PRESCALER_DIV1;
  huart3.AdvancedInit.AdvFeatureInit = UART_ADVFEATURE_NO_INIT;
  if (HAL_UART_Init(&huart3) != HAL_OK)
  {
    Error_Handler();
  }
  if (HAL_UARTEx_SetTxFifoThreshold(&huart3, UART_TXFIFO_THRESHOLD_1_8) != HAL_OK)
  {
    Error_Handler();
  }
  if (HAL_UARTEx_SetRxFifoThreshold(&huart3, UART_RXFIFO_THRESHOLD_1_8) != HAL_OK)
  {
    Error_Handler();
  }
  if (HAL_UARTEx_DisableFifoMode(&huart3) != HAL_OK)
  {
    Error_Handler();
  }

}

static void MX_DMA_Init(void)
{

  /* DMA controller clock enable */
  __HAL_RCC_DMA1_CLK_ENABLE();

  /* DMA interrupt init */
  /* DMA1_Stream0_IRQn interrupt configuration */
  HAL_NVIC_SetPriority(DMA1_Stream0_IRQn, 5, 0);
  HAL_NVIC_EnableIRQ(DMA1_Stream0_IRQn);
  /* DMA1_Stream1_IRQn interrupt configuration */
  HAL_NVIC_SetPriority(DMA1_Stream1_IRQn, 5, 0);
  HAL_NVIC_EnableIRQ(DMA1_Stream1_IRQn);

}

static void MX_GPIO_Init(void)
{
  GPIO_InitTypeDef GPIO_InitStruct = {0};

  /* GPIO Ports Clock Enable */
  __HAL_RCC_GPIOE_CLK_ENABLE();
  __HAL_RCC_GPIOC_CLK_ENABLE();
  __HAL_RCC_GPIOF_CLK_ENABLE();
  __HAL_RCC_GPIOA_CLK_ENABLE();
  __HAL_RCC_GPIOB_CLK_ENABLE();
  __HAL_RCC_GPIOG_CLK_ENABLE();
  __HAL_RCC_GPIOD_CLK_ENABLE();

  /*Configure GPIO pin Output Level */
  HAL_GPIO_WritePin(GPIOE, GPIO_PIN_2, GPIO_PIN_RESET);

  /*Configure GPIO pin Output Level */
  HAL_GPIO_WritePin(GPIOG, GPIO_PIN_0|GPIO_PIN_1|GPIO_PIN_2|GPIO_PIN_3
                          |GPIO_PIN_4, GPIO_PIN_RESET);

  /*Configure GPIO pin Output Level */
  HAL_GPIO_WritePin(GPIOD, GPIO_PIN_2|GPIO_PIN_3|GPIO_PIN_4|GPIO_PIN_5
                          |GPIO_PIN_6|GPIO_PIN_7, GPIO_PIN_RESET);

  /*Configure GPIO pin : PE2 */
  GPIO_InitStruct.Pin = GPIO_PIN_2;
  GPIO_InitStruct.Mode = GPIO_MODE_OUTPUT_PP;
  GPIO_InitStruct.Pull = GPIO_NOPULL;
  GPIO_InitStruct.Speed = GPIO_SPEED_FREQ_LOW;
  HAL_GPIO_Init(GPIOE, &GPIO_InitStruct);

  /*Configure GPIO pin : PE3 */
  GPIO_InitStruct.Pin = GPIO_PIN_3;
  GPIO_InitStruct.Mode = GPIO_MODE_IT_FALLING;
  GPIO_InitStruct.Pull = GPIO_PULLUP;
  HAL_GPIO_Init(GPIOE, &GPIO_InitStruct);

  /*Configure GPIO pins : PC13 PC0 PC1 PC4
                           PC5 PC8 */
  GPIO_InitStruct.Pin = GPIO_PIN_13|GPIO_PIN_0|GPIO_PIN_1|GPIO_PIN_4
                          |GPIO_PIN_5|GPIO_PIN_8;
  GPIO_InitStruct.Mode = GPIO_MODE_IT_FALLING;
  GPIO_InitStruct.Pull = GPIO_PULLUP;
  HAL_GPIO_Init(GPIOC, &GPIO_InitStruct);

  /*Configure GPIO pin : PB2 */
  GPIO_InitStruct.Pin = GPIO_PIN_2;
  GPIO_InitStruct.Mode = GPIO_MODE_IT_FALLING;
  GPIO_InitStruct.Pull = GPIO_PULLUP;
  HAL_GPIO_Init(GPIOB, &GPIO_InitStruct);

  /*Configure GPIO pins : PG0 PG1 PG2 PG3
                           PG4 */
  GPIO_InitStruct.Pin = GPIO_PIN_0|GPIO_PIN_1|GPIO_PIN_2|GPIO_PIN_3
                          |GPIO_PIN_4;
  GPIO_InitStruct.Mode = GPIO_MODE_OUTPUT_PP;
  GPIO_InitStruct.Pull = GPIO_NOPULL;
  GPIO_InitStruct.Speed = GPIO_SPEED_FREQ_LOW;
  HAL_GPIO_Init(GPIOG, &GPIO_InitStruct);

  /*Configure GPIO pins : PD10 PD11 PD14 PD15 */
  GPIO_InitStruct.Pin = GPIO_PIN_10|GPIO_PIN_11|GPIO_PIN_14|GPIO_PIN_15;
  GPIO_InitStruct.Mode = GPIO_MODE_IT_FALLING;
  GPIO_InitStruct.Pull = GPIO_PULLUP;
  HAL_GPIO_Init(GPIOD, &GPIO_InitStruct);

  /*Configure GPIO pins : PD2 PD3 PD4 PD5
                           PD6 PD7 */
  GPIO_InitStruct.Pin = GPIO_PIN_2|GPIO_PIN_3|GPIO_PIN_4|GPIO_PIN_5
                          |GPIO_PIN_6|GPIO_PIN_7;
  GPIO_InitStruct.Mode = GPIO_MODE_OUTPUT_PP;
  GPIO_InitStruct.Pull = GPIO_NOPULL;
  GPIO_InitStruct.Speed = GPIO_SPEED_FREQ_LOW;
  HAL_GPIO_Init(GPIOD, &GPIO_InitStruct);

  /* EXTI interrupt init*/
  HAL_NVIC_SetPriority(EXTI0_IRQn, 5, 0);
  HAL_NVIC_EnableIRQ(EXTI0_IRQn);

  HAL_NVIC_SetPriority(EXTI1_IRQn, 5, 0);
  HAL_NVIC_EnableIRQ(EXTI1_IRQn);

  HAL_NVIC_SetPriority(EXTI2_IRQn, 5, 0);
  HAL_NVIC_EnableIRQ(EXTI2_IRQn);

  HAL_NVIC_SetPriority(EXTI3_IRQn, 5, 0);
  HAL_NVIC_EnableIRQ(EXTI3_IRQn);

  HAL_NVIC_SetPriority(EXTI15_10_IRQn, 5, 0);
  HAL_NVIC_EnableIRQ(EXTI15_10_IRQn);

}

void StartDefaultTask(void *argument)
{
  /* USER CODE BEGIN 5 */
  extern void StartDefaultTask_rtos(void *argument);
  StartDefaultTask_rtos(argument);
  /* Infinite loop */
  for(;;)
  {
    osDelay(1);
  }
  /* USER CODE END 5 */
}

 /* MPU Configuration */

void MPU_Config(void)
{
  MPU_Region_InitTypeDef MPU_InitStruct = {0};

  /* Disables the MPU */
  HAL_MPU_Disable();

  /** Initializes and configures the Region and the memory to be protected
  */
  MPU_InitStruct.Enable = MPU_REGION_ENABLE;
  MPU_InitStruct.Number = MPU_REGION_NUMBER0;
  MPU_InitStruct.BaseAddress = 0x0;
  MPU_InitStruct.Size = MPU_REGION_SIZE_4GB;
  MPU_InitStruct.SubRegionDisable = 0x87;
  MPU_InitStruct.TypeExtField = MPU_TEX_LEVEL0;
  MPU_InitStruct.AccessPermission = MPU_REGION_NO_ACCESS;
  MPU_InitStruct.DisableExec = MPU_INSTRUCTION_ACCESS_DISABLE;
  MPU_InitStruct.IsShareable = MPU_ACCESS_SHAREABLE;
  MPU_InitStruct.IsCacheable = MPU_ACCESS_NOT_CACHEABLE;
  MPU_InitStruct.IsBufferable = MPU_ACCESS_NOT_BUFFERABLE;

  HAL_MPU_ConfigRegion(&MPU_InitStruct);
  /* Enables the MPU */
  HAL_MPU_Enable(MPU_PRIVILEGED_DEFAULT);

}

void HAL_TIM_PeriodElapsedCallback(TIM_HandleTypeDef *htim)
{
  if (htim->Instance == TIM6)
  {
    HAL_IncTick();
  }
  /* USER CODE BEGIN Callback 1 */
  extern void HAL_TIM_PeriodElapsedCallback_rtos(TIM_HandleTypeDef *htim);
  HAL_TIM_PeriodElapsedCallback_rtos(htim);
  /* USER CODE END Callback 1 */
}

void Error_Handler(void)
{
  __disable_irq();
  while (1)
  {
  }
}
